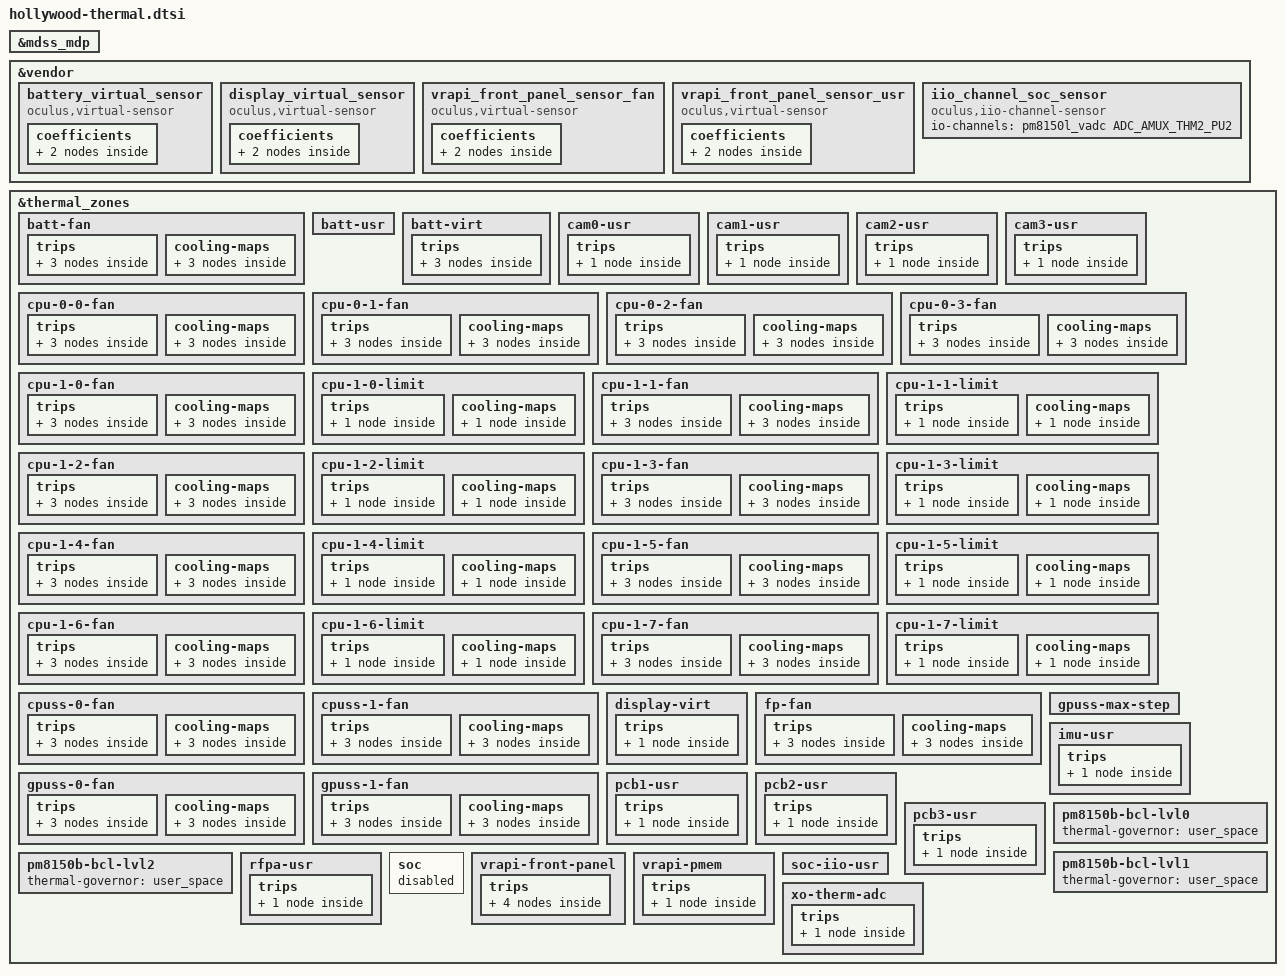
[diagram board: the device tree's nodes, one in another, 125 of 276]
&mdss_mdp {
	#cooling-cells = <2>;
};

&vendor {
	battery_virtual_sensor: battery_virtual_sensor {
		compatible = "oculus,virtual-sensor";
		status = "ok";
		#thermal-sensor-cells = <0>;

		io-channels = <&pm8150l_vadc ADC_AMUX_THM2_PU2>;
		io-channel-names = "soc_temp";

		fallback-thermal-zone = "batt-usr";
		fallback-scaling-factor = <100>;
		fallback-tolerance = <8000>;

		thermal-zones = "batt-usr", "pcb3-usr", "pcb2-usr", "pcb1-usr",
				"rfpa-usr", "imu-usr";
		thermal-zone-scaling-factors = <100 1 1 1 1 1>;

		io-scaling-factors = <1>;

		internal-polling-delay = <1000>;

		coefficients {
			charging {
				tz-coefficients = <10000 0 0 0 0 0>;
				tz-slope-coefficients = <0 0 0 0 0 0>;
				io-coefficients = <0>;
				io-slope-coefficients = <0>;
				intercept = <0>;
			};
			discharging {
				tz-coefficients = <10799 5790 (-2178) (-4030) (-6841) 6364>;
				tz-slope-coefficients = <0 0 0 0 0 0>;
				io-coefficients = <(-899)>;
				io-slope-coefficients = <0>;
				intercept = <4261>;
			};
		};
	};

	display_virtual_sensor: display_virtual_sensor {
		compatible = "oculus,virtual-sensor";
		status = "ok";
		#thermal-sensor-cells = <0>;

		io-channels = <&pm8150l_vadc ADC_AMUX_THM2_PU2>;
		io-channel-names = "soc_temp";

		thermal-zones = "pcb3-usr", "pcb2-usr", "pcb1-usr", "rfpa-usr",
				"imu-usr";

		internal-polling-delay = <1000>;

		coefficients {
			charging {
				tz-coefficients = <14926 305 (-3087) (-8890) 13763>;
				tz-slope-coefficients = <12822 (-1739) 18749 25948 3744>;
				io-coefficients = <(-6495)>;
				io-slope-coefficients = <31148>;
				intercept = <(-3354)>;
			};
			discharging {
				tz-coefficients = <14926 305 (-3087) (-8890) 13763>;
				tz-slope-coefficients = <12822 (-1739) 18749 25948 3744>;
				io-coefficients = <(-6495)>;
				io-slope-coefficients = <31148>;
				intercept = <(-3354)>;
			};
		};
	};

	vrapi_front_panel_sensor_fan: vrapi_front_panel_sensor_fan {
		compatible = "oculus,virtual-sensor";
		status = "ok";
		#thermal-sensor-cells = <0>;

		io-channels = <&pm8150l_vadc ADC_AMUX_THM2_PU2>;
		io-channel-names = "soc_temp";

		thermal-zones = "pcb3-usr", "pcb2-usr", "pcb1-usr", "rfpa-usr",
				"imu-usr";

		internal-polling-delay = <1000>;

		coefficients {
			charging {
				tz-coefficients = <2122 (-933) 18156 (-10527) (-1730)>;
				tz-slope-coefficients = <(-223) 2052 (-8703) 1796 6275>;
				io-coefficients = <106>;
				io-slope-coefficients = <(-82)>;
				intercept = <4440>;
			};
			discharging {
				tz-coefficients = <2122 (-933) 18156 (-10527) (-1730)>;
				tz-slope-coefficients = <(-223) 2052 (-8703) 1796 6275>;
				io-coefficients = <106>;
				io-slope-coefficients = <(-82)>;
				intercept = <2940>;
			};
		};
	};

	vrapi_front_panel_sensor_usr: vrapi_front_panel_sensor_usr {
		compatible = "oculus,virtual-sensor";
		status = "ok";
		#thermal-sensor-cells = <0>;

		io-channels = <&pm8150l_vadc ADC_AMUX_THM2_PU2>;
		io-channel-names = "soc_temp";

		thermal-zones = "pcb3-usr", "pcb2-usr", "pcb1-usr", "rfpa-usr",
				"imu-usr";

		internal-polling-delay = <1000>;

		coefficients {
			charging {
				tz-coefficients = <2122 (-933) 18156 (-10527) (-1730)>;
				tz-slope-coefficients = <(-223) 2052 (-8703) 1796 6275>;
				io-coefficients = <106>;
				io-slope-coefficients = <(-82)>;
				intercept = <4440>;
			};
			discharging {
				tz-coefficients = <2122 (-933) 18156 (-10527) (-1730)>;
				tz-slope-coefficients = <(-223) 2052 (-8703) 1796 6275>;
				io-coefficients = <106>;
				io-slope-coefficients = <(-82)>;
				intercept = <2940>;
			};
		};
	};

	iio_channel_soc_sensor: iio_channel_soc_sensor {
		compatible = "oculus,iio-channel-sensor";
		status = "ok";
		#thermal-sensor-cells = <0>;

		io-channels = <&pm8150l_vadc ADC_AMUX_THM2_PU2>;
		io-channel-names = "soc_temp";
	};
};

&thermal_zones {
	batt-fan {
		polling-delay-passive = <100>;
		polling-delay = <1000>;
		thermal-sensors = <&pm8150b_adc_tm ADC_BAT_THERM_PU2>;
		thermal-governor = "single_step";
		wake-capable-sensor;
		trips {
			batt_fan_trip1: batt_fan_trip1 {
				temperature = <45000>;
				hysteresis = <3000>;
				type = "active";
			};

			batt_fan_trip2: batt_fan_trip2 {
				temperature = <50000>;
				hysteresis = <3000>;
				type = "active";
			};

			batt_fan_trip3: batt_fan_trip3 {
				temperature = <55000>;
				hysteresis = <3000>;
				type = "active";
			};
		};

		cooling-maps {
			batt_fan_map1: batt_fan_map1 {
				trip = <&batt_fan_trip1>;
				/* RPM: 4000 - 5000 */
				cooling-device = <&fan 4 5>;
			};

			batt_fan_map2: batt_fan_map2 {
				trip = <&batt_fan_trip2>;
				/* RPM: 4000 - 6000 */
				cooling-device = <&fan 4 6>;
			};

			batt_fan_map3: batt_fan_map3 {
				trip = <&batt_fan_trip3>;
				/* RPM: 4000 - 7000 */
				cooling-device = <&fan 4 7>;
			};
		};
	};

	batt-usr {
		polling-delay-passive = <0>;
		polling-delay = <0>;
		thermal-governor = "user_space";
		thermal-sensors = <&pm8150b_adc_tm ADC_BAT_THERM_PU2>;
	};

	batt-virt {
		polling-delay-passive = <0>;
		polling-delay = <0>;
		thermal-governor = "user_space";
		thermal-sensors = <&battery_virtual_sensor>;
		wake-capable-sensor;
		trips {
			batt_virt_trip0: batt-virt-trip0 {
				temperature = <58500>;
				hysteresis = <2000>;
				type = "passive";
			};
			batt_virt_trip1: batt-virt-trip1 {
				temperature = <60000>;
				hysteresis = <1000>;
				type = "passive";
			};
			batt_virt_trip2: batt-virt-trip2 {
				temperature = <64000>;
				hysteresis = <1000>;
				type = "passive";
			};
		};
	};

	cam0-usr {
		polling-delay-passive = <0>;
		polling-delay = <0>;
		thermal-governor = "user_space";
		thermal-sensors = <&pm8150l_adc_tm ADC_AMUX_THM1_PU2>;
		trips {
			active-config0 {
				temperature = <125000>;
				hysteresis = <1000>;
				type = "passive";
			};
		};
	};

	cam1-usr {
		polling-delay-passive = <0>;
		polling-delay = <0>;
		thermal-governor = "user_space";
		thermal-sensors = <&pm8150l_adc_tm ADC_GPIO1_PU2>;
		trips {
			active-config0 {
				temperature = <125000>;
				hysteresis = <1000>;
				type = "passive";
			};
		};
	};

	cam2-usr {
		polling-delay-passive = <0>;
		polling-delay = <0>;
		thermal-governor = "user_space";
		thermal-sensors = <&pm8150l_adc_tm ADC_GPIO2_PU2>;
		trips {
			active-config0 {
				temperature = <125000>;
				hysteresis = <1000>;
				type = "passive";
			};
		};
	};

	cam3-usr {
		polling-delay-passive = <0>;
		polling-delay = <0>;
		thermal-governor = "user_space";
		thermal-sensors = <&pm8150l_adc_tm ADC_AMUX_THM3_PU2>;
		trips {
			active-config0 {
				temperature = <125000>;
				hysteresis = <1000>;
				type = "passive";
			};
		};
	};

	cpu-0-0-fan {
		polling-delay-passive = <100>;
		polling-delay = <1000>;
		thermal-sensors = <&tsens0 1>;
		thermal-governor = "single_step";
		wake-capable-sensor;
		trips {
			cpu_0_0_fan_trip1: cpu_0_0_fan_trip1 {
				temperature = <70000>;
				hysteresis = <10000>;
				type = "active";
			};

			cpu_0_0_fan_trip2: cpu_0_0_fan_trip2 {
				temperature = <80000>;
				hysteresis = <7000>;
				type = "active";
			};

			cpu_0_0_fan_trip3: cpu_0_0_fan_trip3 {
				temperature = <90000>;
				hysteresis = <7000>;
				type = "active";
			};
		};

		cooling-maps {
			cpu_0_0_fan_map1: cpu_0_0_fan_map1 {
				trip = <&cpu_0_0_fan_trip1>;
				/* rpm: 4000 - 5000 */
				cooling-device = <&fan 4 5>;
			};

			cpu_0_0_fan_map2: cpu_0_0_fan_map2 {
				trip = <&cpu_0_0_fan_trip2>;
				/* rpm: 4000 - 6000 */
				cooling-device = <&fan 4 6>;
			};

			cpu_0_0_fan_map3: cpu_0_0_fan_map3 {
				trip = <&cpu_0_0_fan_trip3>;
				/* rpm: 4000 - 7000 */
				cooling-device = <&fan 4 7>;
			};
		};
	};

	cpu-0-1-fan {
		polling-delay-passive = <100>;
		polling-delay = <1000>;
		thermal-sensors = <&tsens0 2>;
		thermal-governor = "single_step";
		wake-capable-sensor;
		trips {
			cpu_0_1_fan_trip1: cpu_0_1_fan_trip1 {
				temperature = <70000>;
				hysteresis = <10000>;
				type = "active";
			};

			cpu_0_1_fan_trip2: cpu_0_1_fan_trip2 {
				temperature = <80000>;
				hysteresis = <7000>;
				type = "active";
			};

			cpu_0_1_fan_trip3: cpu_0_1_fan_trip3 {
				temperature = <90000>;
				hysteresis = <7000>;
				type = "active";
			};
		};

		cooling-maps {
			cpu_0_1_fan_map1: cpu_0_1_fan_map1 {
				trip = <&cpu_0_1_fan_trip1>;
				/* rpm: 4000 - 5000 */
				cooling-device = <&fan 4 5>;
			};

			cpu_0_1_fan_map2: cpu_0_1_fan_map2 {
				trip = <&cpu_0_1_fan_trip2>;
				/* rpm: 4000 - 6000 */
				cooling-device = <&fan 4 6>;
			};

			cpu_0_1_fan_map3: cpu_0_1_fan_map3 {
				trip = <&cpu_0_1_fan_trip3>;
				/* rpm: 4000 - 7000 */
				cooling-device = <&fan 4 7>;
			};
		};
	};

	cpu-0-2-fan {
		polling-delay-passive = <100>;
		polling-delay = <1000>;
		thermal-sensors = <&tsens0 3>;
		thermal-governor = "single_step";
		wake-capable-sensor;
		trips {
			cpu_0_2_fan_trip1: cpu_0_2_fan_trip1 {
				temperature = <70000>;
				hysteresis = <10000>;
				type = "active";
			};

			cpu_0_2_fan_trip2: cpu_0_2_fan_trip2 {
				temperature = <80000>;
				hysteresis = <7000>;
				type = "active";
			};

			cpu_0_2_fan_trip3: cpu_0_2_fan_trip3 {
				temperature = <90000>;
				hysteresis = <7000>;
				type = "active";
			};
		};

		cooling-maps {
			cpu_0_2_fan_map1: cpu_0_2_fan_map1 {
				trip = <&cpu_0_2_fan_trip1>;
				/* rpm: 4000 - 5000 */
				cooling-device = <&fan 4 5>;
			};

			cpu_0_2_fan_map2: cpu_0_2_fan_map2 {
				trip = <&cpu_0_2_fan_trip2>;
				/* rpm: 4000 - 6000 */
				cooling-device = <&fan 4 6>;
			};

			cpu_0_2_fan_map3: cpu_0_2_fan_map3 {
				trip = <&cpu_0_2_fan_trip3>;
				/* rpm: 4000 - 7000 */
				cooling-device = <&fan 4 7>;
			};
		};
	};

	cpu-0-3-fan {
		polling-delay-passive = <100>;
		polling-delay = <1000>;
		thermal-sensors = <&tsens0 4>;
		thermal-governor = "single_step";
		wake-capable-sensor;
		trips {
			cpu_0_3_fan_trip1: cpu_0_3_fan_trip1 {
				temperature = <70000>;
				hysteresis = <10000>;
				type = "active";
			};

			cpu_0_3_fan_trip2: cpu_0_3_fan_trip2 {
				temperature = <80000>;
				hysteresis = <7000>;
				type = "active";
			};

			cpu_0_3_fan_trip3: cpu_0_3_fan_trip3 {
				temperature = <90000>;
				hysteresis = <7000>;
				type = "active";
			};
		};

		cooling-maps {
			cpu_0_3_fan_map1: cpu_0_3_fan_map1 {
				trip = <&cpu_0_3_fan_trip1>;
				/* rpm: 4000 - 5000 */
				cooling-device = <&fan 4 5>;
			};

			cpu_0_3_fan_map2: cpu_0_3_fan_map2 {
				trip = <&cpu_0_3_fan_trip2>;
				/* rpm: 4000 - 6000 */
				cooling-device = <&fan 4 6>;
			};

			cpu_0_3_fan_map3: cpu_0_3_fan_map3 {
				trip = <&cpu_0_3_fan_trip3>;
				/* rpm: 4000 - 7000 */
				cooling-device = <&fan 4 7>;
			};
		};
	};

	cpu-1-0-fan {
		polling-delay-passive = <100>;
		polling-delay = <1000>;
		thermal-sensors = <&tsens0 7>;
		thermal-governor = "single_step";
		wake-capable-sensor;
		trips {
			cpu_1_0_fan_trip1: cpu_1_0_fan_trip1 {
				temperature = <70000>;
				hysteresis = <10000>;
				type = "active";
			};

			cpu_1_0_fan_trip2: cpu_1_0_fan_trip2 {
				temperature = <80000>;
				hysteresis = <7000>;
				type = "active";
			};

			cpu_1_0_fan_trip3: cpu_1_0_fan_trip3 {
				temperature = <90000>;
				hysteresis = <7000>;
				type = "active";
			};
		};

		cooling-maps {
			cpu_1_0_fan_map1: cpu_1_0_fan_map1 {
				trip = <&cpu_1_0_fan_trip1>;
				/* rpm: 4000 - 5000 */
				cooling-device = <&fan 4 5>;
			};

			cpu_1_0_fan_map2: cpu_1_0_fan_map2 {
				trip = <&cpu_1_0_fan_trip2>;
				/* rpm: 4000 - 6000 */
				cooling-device = <&fan 4 6>;
			};

			cpu_1_0_fan_map3: cpu_1_0_fan_map3 {
				trip = <&cpu_1_0_fan_trip3>;
				/* rpm: 4000 - 7000 */
				cooling-device = <&fan 4 7>;
			};
		};
	};

	cpu-1-0-limit {
		polling-delay-passive = <0>;
		polling-delay = <0>;
		thermal-sensors = <&tsens0 7>;
		thermal-governor = "single_step";
		wake-capable-sensor;
		trips {
			cpus_1_0_limit_trip0: cpus_1_0_limit_trip0 {
				temperature = <90000>;
				hysteresis = <5000>;
				type = "passive";
			};
		};
		cooling-maps {
			cpu_1_0_limit_map0: cpu_1_0_limit_map0 {
				trip = <&cpus_1_0_limit_trip0>;
				cooling-device = <&CPU4 0 10>;
			};
		};
	};

	cpu-1-1-fan {
		polling-delay-passive = <100>;
		polling-delay = <1000>;
		thermal-sensors = <&tsens0 8>;
		thermal-governor = "single_step";
		wake-capable-sensor;
		trips {
			cpu_1_1_fan_trip1: cpu_1_1_fan_trip1 {
				temperature = <70000>;
				hysteresis = <10000>;
				type = "active";
			};

			cpu_1_1_fan_trip2: cpu_1_1_fan_trip2 {
				temperature = <80000>;
				hysteresis = <7000>;
				type = "active";
			};

			cpu_1_1_fan_trip3: cpu_1_1_fan_trip3 {
				temperature = <90000>;
				hysteresis = <7000>;
				type = "active";
			};
		};

		cooling-maps {
			cpu_1_1_fan_map1: cpu_1_1_fan_map1 {
				trip = <&cpu_1_1_fan_trip1>;
				/* rpm: 4000 - 5000 */
				cooling-device = <&fan 4 5>;
			};

			cpu_1_1_fan_map2: cpu_1_1_fan_map2 {
				trip = <&cpu_1_1_fan_trip2>;
				/* rpm: 4000 - 6000 */
				cooling-device = <&fan 4 6>;
			};

			cpu_1_1_fan_map3: cpu_1_1_fan_map3 {
				trip = <&cpu_1_1_fan_trip3>;
				/* rpm: 4000 - 7000 */
				cooling-device = <&fan 4 7>;
			};
		};
	};

	cpu-1-1-limit {
		polling-delay-passive = <0>;
		polling-delay = <0>;
		thermal-sensors = <&tsens0 8>;
		thermal-governor = "single_step";
		wake-capable-sensor;
		trips {
			cpus_1_1_limit_trip0: cpus_1_1_limit_trip0 {
				temperature = <90000>;
				hysteresis = <5000>;
				type = "passive";
			};
		};
		cooling-maps {
			cpu_1_1_limit_map0: cpu_1_1_limit_map0 {
				trip = <&cpus_1_1_limit_trip0>;
				cooling-device = <&CPU4 0 10>;
			};
		};
	};

	cpu-1-2-fan {
		polling-delay-passive = <100>;
		polling-delay = <1000>;
		thermal-sensors = <&tsens0 9>;
		thermal-governor = "single_step";
		wake-capable-sensor;
		trips {
			cpu_1_2_fan_trip1: cpu_1_2_fan_trip1 {
				temperature = <70000>;
				hysteresis = <10000>;
				type = "active";
			};

			cpu_1_2_fan_trip2: cpu_1_2_fan_trip2 {
				temperature = <80000>;
				hysteresis = <7000>;
				type = "active";
			};

			cpu_1_2_fan_trip3: cpu_1_2_fan_trip3 {
				temperature = <90000>;
				hysteresis = <7000>;
				type = "active";
			};
		};

		cooling-maps {
			cpu_1_2_fan_map1: cpu_1_2_fan_map1 {
				trip = <&cpu_1_2_fan_trip1>;
				/* rpm: 4000 - 5000 */
				cooling-device = <&fan 4 5>;
			};

			cpu_1_2_fan_map2: cpu_1_2_fan_map2 {
				trip = <&cpu_1_2_fan_trip2>;
				/* rpm: 4000 - 6000 */
				cooling-device = <&fan 4 6>;
			};

			cpu_1_2_fan_map3: cpu_1_2_fan_map3 {
				trip = <&cpu_1_2_fan_trip3>;
				/* rpm: 4000 - 7000 */
				cooling-device = <&fan 4 7>;
			};
		};
	};

	cpu-1-2-limit {
		polling-delay-passive = <0>;
		polling-delay = <0>;
		thermal-sensors = <&tsens0 9>;
		thermal-governor = "single_step";
		wake-capable-sensor;
		trips {
			cpus_1_2_limit_trip0: cpus_1_2_limit_trip0 {
				temperature = <90000>;
				hysteresis = <5000>;
				type = "passive";
			};
		};
		cooling-maps {
			cpu_1_2_limit_map0: cpu_1_2_limit_map0 {
				trip = <&cpus_1_2_limit_trip0>;
				cooling-device = <&CPU4 0 10>;
			};
		};
	};

	cpu-1-3-fan {
		polling-delay-passive = <100>;
		polling-delay = <1000>;
		thermal-sensors = <&tsens0 10>;
		thermal-governor = "single_step";
		wake-capable-sensor;
		trips {
			cpu_1_3_fan_trip1: cpu_1_3_fan_trip1 {
				temperature = <70000>;
				hysteresis = <10000>;
				type = "active";
			};

			cpu_1_3_fan_trip2: cpu_1_3_fan_trip2 {
				temperature = <80000>;
				hysteresis = <7000>;
				type = "active";
			};

			cpu_1_3_fan_trip3: cpu_1_3_fan_trip3 {
				temperature = <90000>;
				hysteresis = <7000>;
				type = "active";
			};
		};

		cooling-maps {
			cpu_1_3_fan_map1: cpu_1_3_fan_map1 {
				trip = <&cpu_1_3_fan_trip1>;
				/* rpm: 4000 - 5000 */
				cooling-device = <&fan 4 5>;
			};

			cpu_1_3_fan_map2: cpu_1_3_fan_map2 {
				trip = <&cpu_1_3_fan_trip2>;
				/* rpm: 4000 - 6000 */
				cooling-device = <&fan 4 6>;
			};

			cpu_1_3_fan_map3: cpu_1_3_fan_map3 {
				trip = <&cpu_1_3_fan_trip3>;
				/* rpm: 4000 - 7000 */
				cooling-device = <&fan 4 7>;
			};
		};
	};

	cpu-1-3-limit {
		polling-delay-passive = <0>;
		polling-delay = <0>;
		thermal-sensors = <&tsens0 10>;
		thermal-governor = "single_step";
		wake-capable-sensor;
		trips {
			cpus_1_3_limit_trip0: cpus_1_3_limit_trip0 {
				temperature = <90000>;
				hysteresis = <5000>;
				type = "passive";
			};
		};
		cooling-maps {
			cpu_1_3_limit_map0: cpu_1_3_limit_map0 {
				trip = <&cpus_1_3_limit_trip0>;
				cooling-device = <&CPU7 0 17>;
			};
		};
	};

	cpu-1-4-fan {
		polling-delay-passive = <100>;
		polling-delay = <1000>;
		thermal-sensors = <&tsens0 11>;
		thermal-governor = "single_step";
		wake-capable-sensor;
		trips {
			cpu_1_4_fan_trip1: cpu_1_4_fan_trip1 {
				temperature = <70000>;
				hysteresis = <10000>;
				type = "active";
			};

			cpu_1_4_fan_trip2: cpu_1_4_fan_trip2 {
				temperature = <80000>;
				hysteresis = <7000>;
				type = "active";
			};

			cpu_1_4_fan_trip3: cpu_1_4_fan_trip3 {
				temperature = <90000>;
				hysteresis = <7000>;
				type = "active";
			};
		};

		cooling-maps {
			cpu_1_4_fan_map1: cpu_1_4_fan_map1 {
				trip = <&cpu_1_4_fan_trip1>;
				/* rpm: 4000 - 5000 */
				cooling-device = <&fan 4 5>;
			};

			cpu_1_4_fan_map2: cpu_1_4_fan_map2 {
				trip = <&cpu_1_4_fan_trip2>;
				/* rpm: 4000 - 6000 */
				cooling-device = <&fan 4 6>;
			};

			cpu_1_4_fan_map3: cpu_1_4_fan_map3 {
				trip = <&cpu_1_4_fan_trip3>;
				/* rpm: 4000 - 7000 */
				cooling-device = <&fan 4 7>;
			};
		};
	};

	cpu-1-4-limit {
		polling-delay-passive = <0>;
		polling-delay = <0>;
		thermal-sensors = <&tsens0 11>;
		thermal-governor = "single_step";
		wake-capable-sensor;
		trips {
			cpus_1_4_limit_trip0: cpus_1_4_limit_trip0 {
				temperature = <90000>;
				hysteresis = <5000>;
				type = "passive";
			};
		};
		cooling-maps {
			cpu_1_4_limit_map0: cpu_1_4_limit_map0 {
				trip = <&cpus_1_4_limit_trip0>;
				cooling-device = <&CPU4 0 10>;
			};
		};
	};

	cpu-1-5-fan {
		polling-delay-passive = <100>;
		polling-delay = <1000>;
		thermal-sensors = <&tsens0 12>;
		thermal-governor = "single_step";
		wake-capable-sensor;
		trips {
			cpu_1_5_fan_trip1: cpu_1_5_fan_trip1 {
				temperature = <70000>;
				hysteresis = <10000>;
				type = "active";
			};

			cpu_1_5_fan_trip2: cpu_1_5_fan_trip2 {
				temperature = <80000>;
				hysteresis = <7000>;
				type = "active";
			};

			cpu_1_5_fan_trip3: cpu_1_5_fan_trip3 {
				temperature = <90000>;
				hysteresis = <7000>;
				type = "active";
			};
		};

		cooling-maps {
			cpu_1_5_fan_map1: cpu_1_5_fan_map1 {
				trip = <&cpu_1_5_fan_trip1>;
				/* rpm: 4000 - 5000 */
				cooling-device = <&fan 4 5>;
			};

			cpu_1_5_fan_map2: cpu_1_5_fan_map2 {
				trip = <&cpu_1_5_fan_trip2>;
				/* rpm: 4000 - 6000 */
				cooling-device = <&fan 4 6>;
			};

			cpu_1_5_fan_map3: cpu_1_5_fan_map3 {
				trip = <&cpu_1_5_fan_trip3>;
				/* rpm: 4000 - 7000 */
				cooling-device = <&fan 4 7>;
			};
		};
	};

	cpu-1-5-limit {
		polling-delay-passive = <0>;
		polling-delay = <0>;
		thermal-sensors = <&tsens0 12>;
		thermal-governor = "single_step";
		wake-capable-sensor;
		trips {
			cpus_1_5_limit_trip0: cpus_1_5_limit_trip0 {
				temperature = <90000>;
				hysteresis = <5000>;
				type = "passive";
			};
		};
		cooling-maps {
			cpu_1_5_limit_map0: cpu_1_5_limit_map0 {
				trip = <&cpus_1_5_limit_trip0>;
				cooling-device = <&CPU4 0 10>;
			};
		};
	};

	cpu-1-6-fan {
		polling-delay-passive = <100>;
		polling-delay = <1000>;
		thermal-sensors = <&tsens0 13>;
		thermal-governor = "single_step";
		wake-capable-sensor;
		trips {
			cpu_1_6_fan_trip1: cpu_1_6_fan_trip1 {
				temperature = <70000>;
				hysteresis = <10000>;
				type = "active";
			};

			cpu_1_6_fan_trip2: cpu_1_6_fan_trip2 {
				temperature = <80000>;
				hysteresis = <7000>;
				type = "active";
			};

			cpu_1_6_fan_trip3: cpu_1_6_fan_trip3 {
				temperature = <90000>;
				hysteresis = <7000>;
				type = "active";
			};
		};

		cooling-maps {
			cpu_1_6_fan_map1: cpu_1_6_fan_map1 {
				trip = <&cpu_1_6_fan_trip1>;
				/* rpm: 4000 - 5000 */
				cooling-device = <&fan 4 5>;
			};

			cpu_1_6_fan_map2: cpu_1_6_fan_map2 {
				trip = <&cpu_1_6_fan_trip2>;
				/* rpm: 4000 - 6000 */
				cooling-device = <&fan 4 6>;
			};

			cpu_1_6_fan_map3: cpu_1_6_fan_map3 {
				trip = <&cpu_1_6_fan_trip3>;
				/* rpm: 4000 - 7000 */
				cooling-device = <&fan 4 7>;
			};
		};
	};

	cpu-1-6-limit {
		polling-delay-passive = <0>;
		polling-delay = <0>;
		thermal-sensors = <&tsens0 13>;
		thermal-governor = "single_step";
		wake-capable-sensor;
		trips {
			cpus_1_6_limit_trip0: cpus_1_6_limit_trip0 {
				temperature = <90000>;
				hysteresis = <5000>;
				type = "passive";
			};
		};
		cooling-maps {
			cpu_1_6_limit_map0: cpu_1_6_limit_map0 {
				trip = <&cpus_1_6_limit_trip0>;
				cooling-device = <&CPU4 0 10>;
			};
		};
	};

	cpu-1-7-fan {
		polling-delay-passive = <100>;
		polling-delay = <1000>;
		thermal-sensors = <&tsens0 14>;
		thermal-governor = "single_step";
		wake-capable-sensor;
		trips {
			cpu_1_7_fan_trip1: cpu_1_7_fan_trip1 {
				temperature = <70000>;
				hysteresis = <10000>;
				type = "active";
			};

			cpu_1_7_fan_trip2: cpu_1_7_fan_trip2 {
				temperature = <80000>;
				hysteresis = <7000>;
				type = "active";
			};

			cpu_1_7_fan_trip3: cpu_1_7_fan_trip3 {
				temperature = <90000>;
				hysteresis = <7000>;
				type = "active";
			};
		};

		cooling-maps {
			cpu_1_7_fan_map1: cpu_1_7_fan_map1 {
				trip = <&cpu_1_7_fan_trip1>;
				/* rpm: 4000 - 5000 */
				cooling-device = <&fan 4 5>;
			};

			cpu_1_7_fan_map2: cpu_1_7_fan_map2 {
				trip = <&cpu_1_7_fan_trip2>;
				/* rpm: 4000 - 6000 */
				cooling-device = <&fan 4 6>;
			};

			cpu_1_7_fan_map3: cpu_1_7_fan_map3 {
				trip = <&cpu_1_7_fan_trip3>;
				/* rpm: 4000 - 7000 */
				cooling-device = <&fan 4 7>;
			};
		};
	};

	cpu-1-7-limit {
		polling-delay-passive = <0>;
		polling-delay = <0>;
		thermal-sensors = <&tsens0 14>;
		thermal-governor = "single_step";
		wake-capable-sensor;
		trips {
			cpus_1_7_limit_trip0: cpus_1_7_limit_trip0 {
				temperature = <90000>;
				hysteresis = <5000>;
				type = "passive";
			};
		};
		cooling-maps {
			cpu_1_7_limit_map0: cpu_1_7_limit_map0 {
				trip = <&cpus_1_7_limit_trip0>;
				cooling-device = <&CPU7 0 17>;
			};
		};
	};

	cpuss-0-fan {
		polling-delay-passive = <100>;
		polling-delay = <1000>;
		thermal-sensors = <&tsens0 5>;
		thermal-governor = "single_step";
		wake-capable-sensor;
		trips {
			cpuss_0_fan_trip1: cpuss_0_fan_trip1 {
				temperature = <70000>;
				hysteresis = <10000>;
				type = "active";
			};

			cpuss_0_fan_trip2: cpuss_0_fan_trip2 {
				temperature = <80000>;
				hysteresis = <7000>;
				type = "active";
			};

			cpuss_0_fan_trip3: cpuss_0_fan_trip3 {
				temperature = <90000>;
				hysteresis = <7000>;
				type = "active";
			};
		};

		cooling-maps {
			cpuss_0_fan_map1: cpuss_0_fan_map1 {
				trip = <&cpuss_0_fan_trip1>;
				/* rpm: 4000 - 5000 */
				cooling-device = <&fan 4 5>;
			};

			cpuss_0_fan_map2: cpuss_0_fan_map2 {
				trip = <&cpuss_0_fan_trip2>;
				/* rpm: 4000 - 6000 */
				cooling-device = <&fan 4 6>;
			};

			cpuss_0_fan_map3: cpuss_0_fan_map3 {
				trip = <&cpuss_0_fan_trip3>;
				/* rpm: 4000 - 7000 */
				cooling-device = <&fan 4 7>;
			};
		};
	};

	cpuss-1-fan {
		polling-delay-passive = <100>;
		polling-delay = <1000>;
		thermal-sensors = <&tsens0 6>;
		thermal-governor = "single_step";
		wake-capable-sensor;
		trips {
			cpuss_1_fan_trip1: cpuss_1_fan_trip1 {
				temperature = <70000>;
				hysteresis = <10000>;
				type = "active";
			};

			cpuss_1_fan_trip2: cpuss_1_fan_trip2 {
				temperature = <80000>;
				hysteresis = <7000>;
				type = "active";
			};

			cpuss_1_fan_trip3: cpuss_1_fan_trip3 {
				temperature = <90000>;
				hysteresis = <7000>;
				type = "active";
			};
		};

		cooling-maps {
			cpuss_1_fan_map1: cpuss_1_fan_map1 {
				trip = <&cpuss_1_fan_trip1>;
				/* rpm: 4000 - 5000 */
				cooling-device = <&fan 4 5>;
			};

			cpuss_1_fan_map2: cpuss_1_fan_map2 {
				trip = <&cpuss_1_fan_trip2>;
				/* rpm: 4000 - 6000 */
				cooling-device = <&fan 4 6>;
			};

			cpuss_1_fan_map3: cpuss_1_fan_map3 {
				trip = <&cpuss_1_fan_trip3>;
				/* rpm: 4000 - 7000 */
				cooling-device = <&fan 4 7>;
			};
		};
	};

	display-virt {
		polling-delay-passive = <0>;
		polling-delay = <0>;
		thermal-governor = "user_space";
		thermal-sensors = <&display_virtual_sensor>;
		wake-capable-sensor;
		trips {
			active-config0 {
				temperature = <125000>;
				hysteresis = <1000>;
				type = "passive";
			};
		};
	};

	fp-fan {
		polling-delay-passive = <0>;
		polling-delay = <0>;
		thermal-governor = "single_step";
		thermal-sensors = <&vrapi_front_panel_sensor_fan>;
		wake-capable-sensor;
		trips {
			fp_fan_trip1: fp_fan_trip1 {
				temperature = <40000>;
				hysteresis = <2000>;
				type = "active";
			};

			fp_fan_trip2: fp_fan_trip2 {
				temperature = <44000>;
				hysteresis = <2000>;
				type = "active";
			};

			fp_fan_trip3: fp_fan_trip3 {
				temperature = <50000>;
				hysteresis = <2000>;
				type = "active";
			};
		};

		cooling-maps {
			fp_fan_map1: fp_fan_map1 {
				trip = <&fp_fan_trip1>;
				/* RPM: 4000 - 5000 */
				cooling-device = <&fan 4 5>;
			};

			fp_fan_map2: fp_fan_map2 {
				trip = <&fp_fan_trip2>;
				/* RPM: 4000 - 6000 */
				cooling-device = <&fan 4 6>;
			};

			fp_fan_map3: fp_fan_map3 {
				trip = <&fp_fan_trip3>;
				/* RPM: 4000 - 7000 */
				cooling-device = <&fan 4 7>;
			};
		};
	};

	gpuss-0-fan {
		polling-delay-passive = <100>;
		polling-delay = <1000>;
		thermal-sensors = <&tsens0 15>;
		thermal-governor = "single_step";
		wake-capable-sensor;
		trips {
			gpuss_0_fan_trip1: gpuss_0_fan_trip1 {
				temperature = <70000>;
				hysteresis = <10000>;
				type = "active";
			};

			gpuss_0_fan_trip2: gpuss_0_fan_trip2 {
				temperature = <80000>;
				hysteresis = <7000>;
				type = "active";
			};

			gpuss_0_fan_trip3: gpuss_0_fan_trip3 {
				temperature = <90000>;
				hysteresis = <7000>;
				type = "active";
			};
		};

		cooling-maps {
			gpuss_0_fan_map1: gpuss_0_fan_map1 {
				trip = <&gpuss_0_fan_trip1>;
				/* RPM: 4000 - 5000 */
				cooling-device = <&fan 4 5>;
			};

			gpuss_0_fan_map2: gpuss-0_fan_map2 {
				trip = <&gpuss_0_fan_trip2>;
				/* RPM: 4000 - 6000 */
				cooling-device = <&fan 4 6>;
			};

			gpuss_0_fan_map3: gpuss_0_fan_map3 {
				trip = <&gpuss_0_fan_trip3>;
				/* rpm: 4000 - 7000 */
				cooling-device = <&fan 4 7>;
			};
		};
	};

	gpuss-1-fan {
		polling-delay-passive = <100>;
		polling-delay = <1000>;
		thermal-sensors = <&tsens1 8>;
		thermal-governor = "single_step";
		wake-capable-sensor;
		trips {
			gpuss_1_fan_trip1: gpuss_1_fan_trip1 {
				temperature = <70000>;
				hysteresis = <10000>;
				type = "active";
			};

			gpuss_1_fan_trip2: gpuss_1_fan_trip2 {
				temperature = <80000>;
				hysteresis = <7000>;
				type = "active";
			};

			gpuss_1_fan_trip3: gpuss_1_fan_trip3 {
				temperature = <90000>;
				hysteresis = <7000>;
				type = "active";
			};
		};

		cooling-maps {
			gpuss_1_fan_map1: gpuss_1_fan_map1 {
				trip = <&gpuss_1_fan_trip1>;
				/* RPM: 4000 - 5000 */
				cooling-device = <&fan 4 5>;
			};

			gpuss_1_fan_map2: gpuss_1_fan_map2 {
				trip = <&gpuss_1_fan_trip2>;
				/* RPM: 4000 - 6000 */
				cooling-device = <&fan 4 6>;
			};

			gpuss_1_fan_map3: gpuss_1_fan_map3 {
				trip = <&gpuss_1_fan_trip3>;
				/* rpm: 4000 - 7000 */
				cooling-device = <&fan 4 7>;
			};
		};
	};

	gpuss-max-step {
		polling-delay-passive = <0>;
		polling-delay = <0>;
	};

	imu-usr {
		polling-delay-passive = <0>;
		polling-delay = <0>;
		thermal-governor = "user_space";
		thermal-sensors = <&pm8150_adc_tm ADC_AMUX_THM1_PU2>;
		trips {
			active-config0 {
				temperature = <125000>;
				hysteresis = <1000>;
				type = "passive";
			};
		};
	};

	pcb1-usr {
		polling-delay-passive = <0>;
		polling-delay = <0>;
		thermal-governor = "user_space";
		thermal-sensors = <&pm8150b_adc_tm ADC_AMUX_THM4_PU2>;
		trips {
			active-config0 {
				temperature = <125000>;
				hysteresis = <1000>;
				type = "passive";
			};
		};
	};

	pcb2-usr {
		polling-delay-passive = <0>;
		polling-delay = <0>;
		thermal-governor = "user_space";
		thermal-sensors = <&pm8150b_adc_tm ADC_GPIO2_PU2>;
		trips {
			active-config0 {
				temperature = <125000>;
				hysteresis = <1000>;
				type = "passive";
			};
		};
	};

	pcb3-usr {
		polling-delay-passive = <0>;
		polling-delay = <0>;
		thermal-governor = "user_space";
		thermal-sensors = <&pm8150b_adc_tm ADC_AMUX_THM2_PU2>;
		trips {
			active-config0 {
				temperature = <125000>;
				hysteresis = <1000>;
				type = "passive";
			};
		};
	};

	pm8150b-bcl-lvl0 {
		thermal-governor = "user_space";
	};

	pm8150b-bcl-lvl1 {
		thermal-governor = "user_space";
	};

	pm8150b-bcl-lvl2 {
		thermal-governor = "user_space";
	};

	rfpa-usr {
		polling-delay-passive = <0>;
		polling-delay = <0>;
		thermal-governor = "user_space";
		thermal-sensors = <&pm8150_adc_tm ADC_AMUX_THM2_PU2>;
		trips {
			active-config0 {
				temperature = <125000>;
				hysteresis = <1000>;
				type = "passive";
			};
		};
	};

	soc {
		status = "disabled";
	};

	vrapi-front-panel {
		polling-delay-passive = <0>;
		polling-delay = <0>;
		thermal-governor = "user_space";
		thermal-sensors = <&vrapi_front_panel_sensor_usr>;
		wake-capable-sensor;
		trips {
			virt_trip0: virt-trip0 {
				temperature = <85000>;
				hysteresis = <1000>;
				type = "passive";
			};
			virt_trip1: virt-trip1 {
				temperature = <95000>;
				hysteresis = <1000>;
				type = "passive";
			};
			virt_trip2: virt-trip2 {
				temperature = <115000>;
				hysteresis = <1000>;
				type = "passive";
			};
			virt_trip3: virt-trip3 {
				temperature = <125000>;
				hysteresis = <1000>;
				type = "passive";
			};
		};
	};

	vrapi-pmem {
		polling-delay-passive = <0>;
		polling-delay = <0>;
		thermal-sensors = <&tsens1 3>;
		thermal-governor = "user_space";
		wake-capable-sensor;
		trips {
			pop_trip: pop-trip {
				temperature = <95000>;
				hysteresis = <1000>;
				type = "passive";
			};
		};
	};

	soc-iio-usr {
		polling-delay-passive = <0>;
		polling-delay = <0>;
		thermal-governor = "user_space";
		thermal-sensors = <&iio_channel_soc_sensor>;
		wake-capable-sensor;
	};

	xo-therm-adc {
		polling-delay-passive = <0>;
		polling-delay = <0>;
		thermal-governor = "user_space";
		thermal-sensors = <&pm8150_adc_tm ADC_XO_THERM_PU2>;
		trips {
			active-config0 {
				temperature = <125000>;
				hysteresis = <1000>;
				type = "passive";
			};
		};
	};
};
